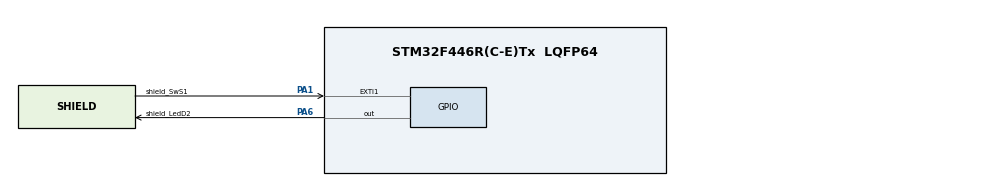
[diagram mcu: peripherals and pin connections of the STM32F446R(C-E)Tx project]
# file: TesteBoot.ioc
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Mcu.Family=STM32F4
Mcu.Name=STM32F446R(C-E)Tx
Mcu.Package=LQFP64
NVIC.EXTI1_IRQn=true\:0\:0\:false\:false\:true\:true\:true\:true
NVIC.PriorityGroup=NVIC_PRIORITYGROUP_4
PA1.GPIO_Label=shield_SwS1
PA1.GPIO_ModeDefaultEXTI=GPIO_MODE_IT_FALLING
PA1.Signal=GPXTI1
PA6.GPIO_Label=shield_LedD2
PA6.GPIO_ModeDefaultOutputPP=GPIO_MODE_OUTPUT_OD
PA6.GPIO_PuPd=GPIO_NOPULL
PA6.PinState=GPIO_PIN_SET
PA6.Signal=GPIO_Output
ProjectManager.HeapSize=0x200
ProjectManager.StackSize=0x400
ProjectManager.TargetToolchain=STM32CubeIDE
RCC.CortexFreq_Value=16000000
RCC.USBFreq_Value=96000000
RCC.VCOOutputFreq_Value=192000000
board=custom

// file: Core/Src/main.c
/* USER CODE BEGIN Header */
/**
  ******************************************************************************
  * @file           : main.c
  * @brief          : Main program body
  ******************************************************************************
  * @attention
  *
  * Copyright (c) 2025 STMicroelectronics.
  * All rights reserved.
  *
  * This software is licensed under terms that can be found in the LICENSE file
  * in the root directory of this software component.
  * If no LICENSE file comes with this software, it is provided AS-IS.
  *
  ******************************************************************************
  */
/* USER CODE END Header */
#include "main.h"
#include "stm32f4xx_hal.h"
#include <stdbool.h>

/* USER CODE BEGIN PTD */

typedef void (*pFunction)(void);

/* USER CODE END PTD */

/* USER CODE BEGIN PD */

#define APP_ADDR   ((uint32_t)0x08010000)  // início da aplicação (Setor 4)

/* USER CODE END PD */

void SystemClock_Config(void);
static void MX_GPIO_Init(void);

/* USER CODE BEGIN 0 */

static void jump_to_application(void)
{
    __disable_irq();

    // 1) Parar e limpar SysTick
    SysTick->CTRL = 0;
    SysTick->LOAD = 0;
    SysTick->VAL  = 0;

    // 2) Limpar pendências de exceções
    SCB->ICSR |= SCB_ICSR_PENDSTCLR_Msk | SCB_ICSR_PENDSVCLR_Msk;

    // 3) Desabilitar e limpar NVIC
    for (uint32_t i = 0; i < 8; i++) {
        NVIC->ICER[i] = 0xFFFFFFFF;
        NVIC->ICPR[i] = 0xFFFFFFFF;
    }

    // 4) Limpar status de Faults
    SCB->CFSR = SCB->CFSR;
    SCB->HFSR = SCB->HFSR;
    SCB->DFSR = SCB->DFSR;
    SCB->SHCSR = 0;

    // 5) Limpar pendências EXTI (evita “flag latente”)
    EXTI->PR = 0x00FFFFFFU; // write-1-to-clear

    // ==============================================================
    // ALTERAÇÕES SUGERIDAS A PARTIR DAQUI
    // ==============================================================

    // 6.a) Resetar e liberar o SYSCFG (Importante para o MUX do EXTI)
    __HAL_RCC_SYSCFG_FORCE_RESET();
    __HAL_RCC_SYSCFG_RELEASE_RESET();

    // 6.b) Desabilitar CLOCKS de todos os GPIOs e periféricos do bootloader
    // Isso força a aplicação a reconfigurar tudo do zero.
    __HAL_RCC_GPIOA_CLK_DISABLE();
    __HAL_RCC_GPIOB_CLK_DISABLE();
    __HAL_RCC_GPIOC_CLK_DISABLE();
    __HAL_RCC_GPIOD_CLK_DISABLE();
    __HAL_RCC_GPIOE_CLK_DISABLE();
    __HAL_RCC_GPIOF_CLK_DISABLE();
    __HAL_RCC_GPIOG_CLK_DISABLE();
    __HAL_RCC_GPIOH_CLK_DISABLE();
    // Adicione outros periféricos que o BOOTLOADER usou (UART, SPI, etc.) se necessário
    // Exemplo: __HAL_RCC_USART2_CLK_DISABLE();

    // 6.c) Deinit HAL/periféricos (função que você já tinha)
    HAL_DeInit();

    // ==============================================================
    // FIM DAS ALTERAÇÕES
    // ==============================================================

    // 7) Validar imagem da App
    uint32_t app_msp   = *(__IO uint32_t*)APP_ADDR;
    uint32_t app_reset = *(__IO uint32_t*)(APP_ADDR + 4);
    if ((app_msp & 0x2FF00000U) != 0x20000000U || (app_reset & 1U) == 0U) {
        // Validação falhou, resetar o sistema
        NVIC_SystemReset();
    }

    // 8) Garantir Thread Mode usando MSP (não PSP)
    __set_CONTROL(0);  // SPSEL=0, nPRIV=0
    __DSB(); __ISB();

    // 9) Zerar BASEPRI (se bootloader usou seções críticas)
    __set_BASEPRI(0);

    // 10) VTOR da app (Você já tinha isso corretamente)
    SCB->VTOR = APP_ADDR;    // alinhado a 0x200
    __DSB(); __ISB(); // Barreiras de memória para garantir a ordem

    // 11) MSP da app
    __set_MSP(app_msp);
    __DSB(); __ISB(); // Barreiras de memória

    // 12) Saltar para Reset_Handler da app (bit0=1 já vem correto)
    ((pFunction)app_reset)();

    // Se a aplicação retornar (o que não deveria), resetar
    NVIC_SystemReset();
}

bool flag_jump = false;
void HAL_GPIO_EXTI_Callback(uint16_t GPIO_Pin)
{
	if(GPIO_Pin == shield_SwS1_Pin)
	{
//		jump_to_application(APP_ADDR);
		flag_jump = true;
	}
}

/* USER CODE END 0 */

int main(void)
{

  /* MCU Configuration--------------------------------------------------------*/

  /* Reset of all peripherals, Initializes the Flash interface and the Systick. */
  HAL_Init();

  /* Configure the system clock */
  SystemClock_Config();
  __enable_irq();       // <<< habilita PRIMASK=0

  /* Initialize all configured peripherals */
  MX_GPIO_Init();

  /* Infinite loop */
  /* USER CODE BEGIN WHILE */
  int i = 5;
  while (i)
  {

	 HAL_GPIO_TogglePin(shield_LedD2_GPIO_Port, shield_LedD2_Pin);
	 HAL_Delay(200);
	 HAL_GPIO_TogglePin(shield_LedD2_GPIO_Port, shield_LedD2_Pin);
	 HAL_Delay(200);
	 i--;

    /* USER CODE END WHILE */

    /* USER CODE BEGIN 3 */
  }

  while(1)
  {
	  if(flag_jump)
		  jump_to_application();

  }
  /* USER CODE END 3 */
}

void SystemClock_Config(void)
{
  RCC_OscInitTypeDef RCC_OscInitStruct = {0};
  RCC_ClkInitTypeDef RCC_ClkInitStruct = {0};

  /** Configure the main internal regulator output voltage
  */
  __HAL_RCC_PWR_CLK_ENABLE();
  __HAL_PWR_VOLTAGESCALING_CONFIG(PWR_REGULATOR_VOLTAGE_SCALE3);

  /** Initializes the RCC Oscillators according to the specified parameters
  * in the RCC_OscInitTypeDef structure.
  */
  RCC_OscInitStruct.OscillatorType = RCC_OSCILLATORTYPE_HSI;
  RCC_OscInitStruct.HSIState = RCC_HSI_ON;
  RCC_OscInitStruct.HSICalibrationValue = RCC_HSICALIBRATION_DEFAULT;
  RCC_OscInitStruct.PLL.PLLState = RCC_PLL_NONE;
  if (HAL_RCC_OscConfig(&RCC_OscInitStruct) != HAL_OK)
  {
    Error_Handler();
  }

  /** Initializes the CPU, AHB and APB buses clocks
  */
  RCC_ClkInitStruct.ClockType = RCC_CLOCKTYPE_HCLK|RCC_CLOCKTYPE_SYSCLK
                              |RCC_CLOCKTYPE_PCLK1|RCC_CLOCKTYPE_PCLK2;
  RCC_ClkInitStruct.SYSCLKSource = RCC_SYSCLKSOURCE_HSI;
  RCC_ClkInitStruct.AHBCLKDivider = RCC_SYSCLK_DIV1;
  RCC_ClkInitStruct.APB1CLKDivider = RCC_HCLK_DIV1;
  RCC_ClkInitStruct.APB2CLKDivider = RCC_HCLK_DIV1;

  if (HAL_RCC_ClockConfig(&RCC_ClkInitStruct, FLASH_LATENCY_0) != HAL_OK)
  {
    Error_Handler();
  }
}

static void MX_GPIO_Init(void)
{
  GPIO_InitTypeDef GPIO_InitStruct = {0};

  /* GPIO Ports Clock Enable */
  __HAL_RCC_GPIOA_CLK_ENABLE();

  /*Configure GPIO pin Output Level */
  HAL_GPIO_WritePin(shield_LedD2_GPIO_Port, shield_LedD2_Pin, GPIO_PIN_SET);

  /*Configure GPIO pin : shield_SwS1_Pin */
  GPIO_InitStruct.Pin = shield_SwS1_Pin;
  GPIO_InitStruct.Mode = GPIO_MODE_IT_FALLING;
  GPIO_InitStruct.Pull = GPIO_NOPULL;
  HAL_GPIO_Init(shield_SwS1_GPIO_Port, &GPIO_InitStruct);

  /*Configure GPIO pin : shield_LedD2_Pin */
  GPIO_InitStruct.Pin = shield_LedD2_Pin;
  GPIO_InitStruct.Mode = GPIO_MODE_OUTPUT_OD;
  GPIO_InitStruct.Pull = GPIO_NOPULL;
  GPIO_InitStruct.Speed = GPIO_SPEED_FREQ_LOW;
  HAL_GPIO_Init(shield_LedD2_GPIO_Port, &GPIO_InitStruct);

  /* EXTI interrupt init*/
  HAL_NVIC_SetPriority(EXTI1_IRQn, 0, 0);
  HAL_NVIC_EnableIRQ(EXTI1_IRQn);

}

void Error_Handler(void)
{
  __disable_irq();
  while (1)
  {
  }
}
